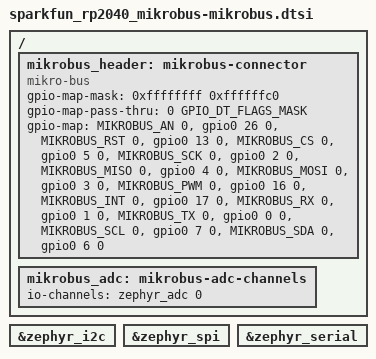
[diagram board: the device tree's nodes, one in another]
/*
 * SPDX-FileCopyrightText: Copyright (c) 2026 Navimatix GmbH
 * SPDX-FileCopyrightText: Copyright (c) 2026 TiaC Systems
 * SPDX-License-Identifier: Apache-2.0
 */

#include <zephyr/dt-bindings/gpio/gpio.h>
#include <zephyr/dt-bindings/gpio/mikro-bus.h>

/ {
	mikrobus_header: mikrobus-connector {
		compatible = "mikro-bus";
		#gpio-cells = <2>;
		gpio-map-mask = <0xffffffff 0xffffffc0>;
		gpio-map-pass-thru = <0 GPIO_DT_FLAGS_MASK>;
		gpio-map = <MIKROBUS_AN 0 &gpio0 26 0>,
			   <MIKROBUS_RST 0 &gpio0 13 0>,
			   <MIKROBUS_CS 0 &gpio0 5 0>,
			   <MIKROBUS_SCK 0 &gpio0 2 0>,
			   <MIKROBUS_MISO 0 &gpio0 4 0>,
			   <MIKROBUS_MOSI 0 &gpio0 3 0>,
			   <MIKROBUS_PWM 0 &gpio0 16 0>,
			   <MIKROBUS_INT 0 &gpio0 17 0>,
			   <MIKROBUS_RX 0 &gpio0 1 0>,
			   <MIKROBUS_TX 0 &gpio0 0 0>,
			   <MIKROBUS_SCL 0 &gpio0 7 0>,
			   <MIKROBUS_SDA 0 &gpio0 6 0>;
	};

	mikrobus_adc: mikrobus-adc-channels {
		io-channels = <&zephyr_adc 0>;
	};
};

mikrobus_i2c: &zephyr_i2c {
	status = "okay";
};

mikrobus_spi: &zephyr_spi {
	status = "okay";
};

mikrobus_serial: &zephyr_serial {
	status = "okay";
};
